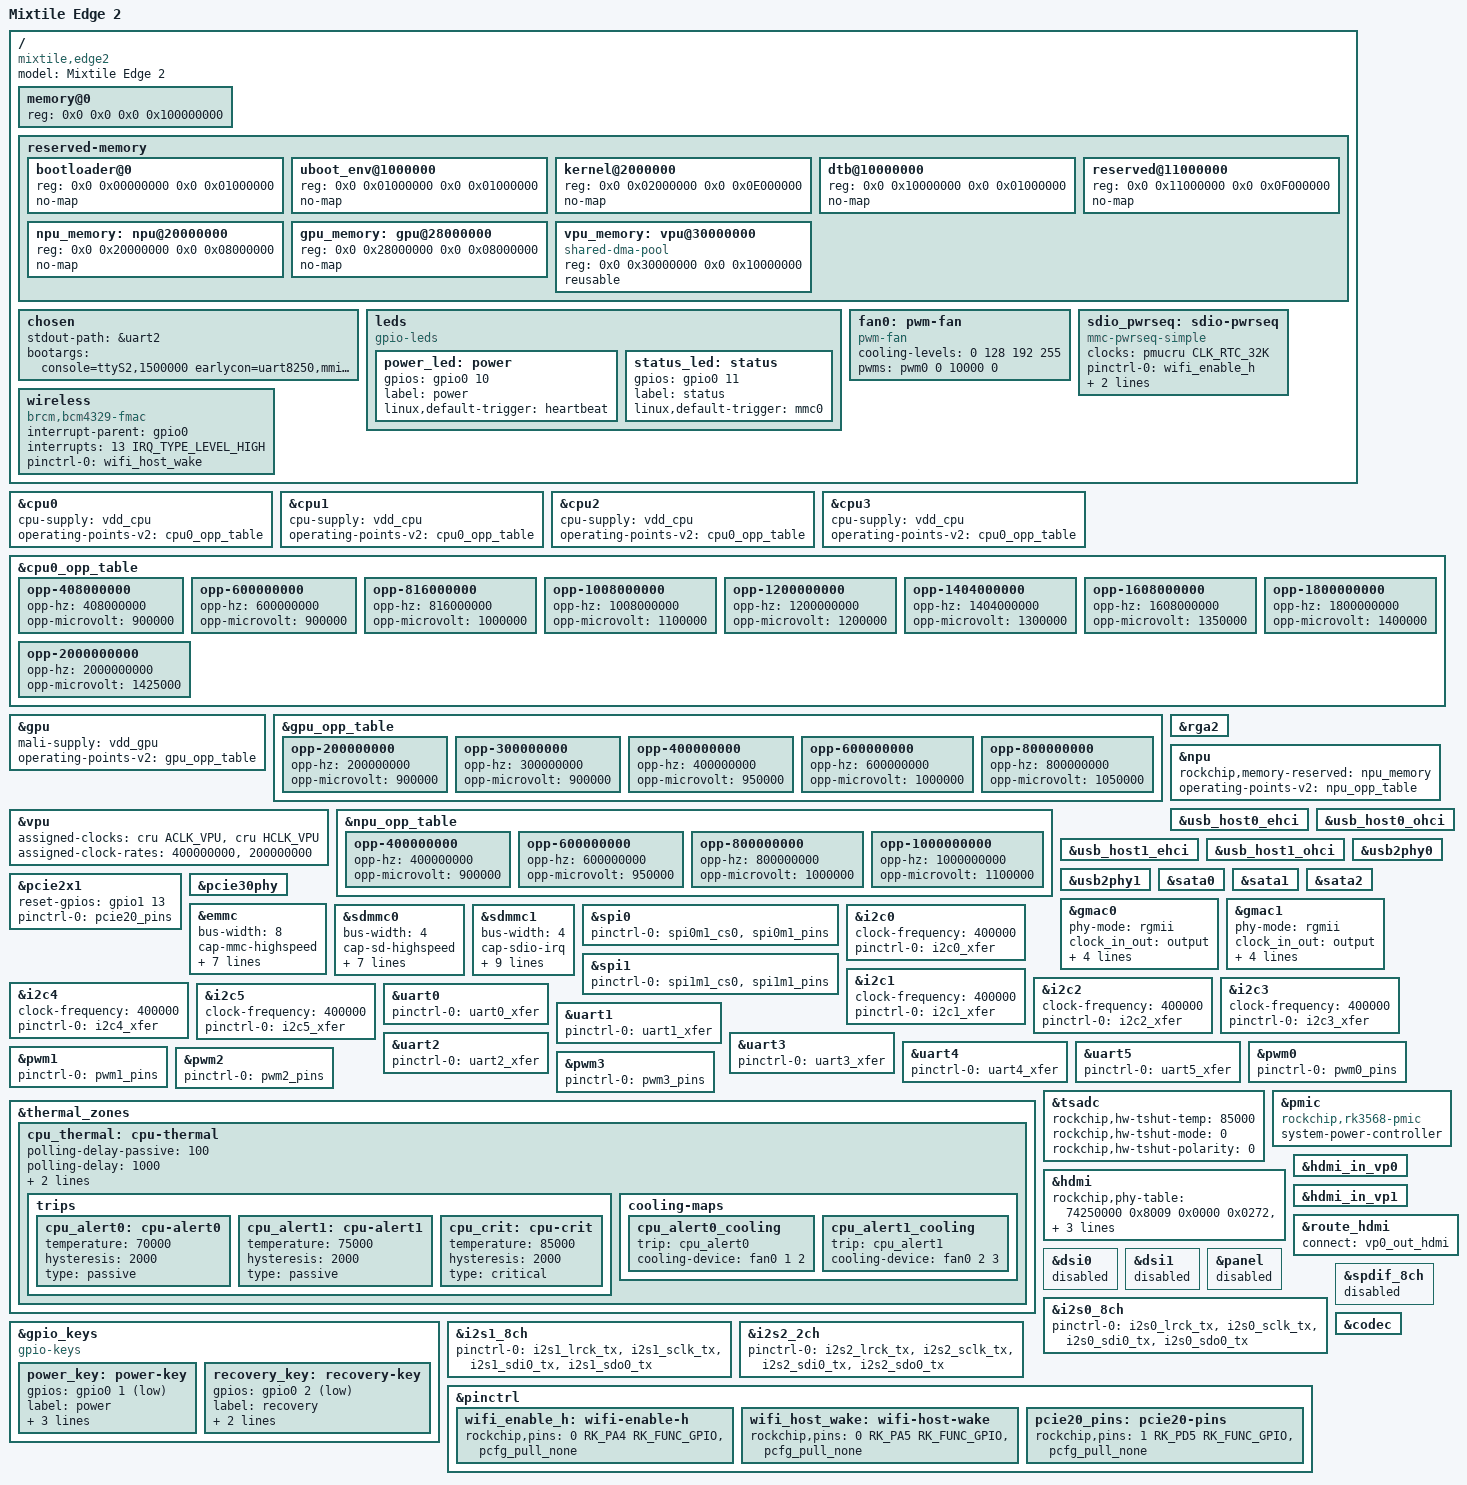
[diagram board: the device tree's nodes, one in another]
// SPDX-License-Identifier: (GPL-2.0+ OR MIT)
/*
 * Device Tree for Mixtile Edge 2
 * Based on Rockchip RK3568
 *
 * Copyright (C) 2024 Sebastian
 * All rights reserved.
 */

/dts-v1/;
#include "rk3568.dtsi"

/ {
	model = "Mixtile Edge 2";
	compatible = "mixtile,edge2", "rockchip,rk3568";

	/* Memory Configuration - 4GB LPDDR4 */
	memory@0 {
		device_type = "memory";
		reg = <0x0 0x0 0x0 0x100000000>;
	};

	/* Reserved Memory Regions */
	reserved-memory {
		#address-cells = <2>;
		#size-cells = <2>;
		ranges;

		/* Bootloader Region */
		bootloader@0 {
			reg = <0x0 0x00000000 0x0 0x01000000>;
			no-map;
			status = "okay";
		};

		/* U-Boot Environment */
		uboot_env@1000000 {
			reg = <0x0 0x01000000 0x0 0x01000000>;
			no-map;
			status = "okay";
		};

		/* Linux Kernel */
		kernel@2000000 {
			reg = <0x0 0x02000000 0x0 0x0E000000>;
			no-map;
			status = "okay";
		};

		/* Device Tree Blob */
		dtb@10000000 {
			reg = <0x0 0x10000000 0x0 0x01000000>;
			no-map;
			status = "okay";
		};

		/* Reserved System Region */
		reserved@11000000 {
			reg = <0x0 0x11000000 0x0 0x0F000000>;
			no-map;
			status = "okay";
		};

		/* NPU Memory Pool - 128MB */
		npu_memory: npu@20000000 {
			reg = <0x0 0x20000000 0x0 0x08000000>;
			no-map;
			status = "okay";
		};

		/* GPU Memory Pool - 128MB */
		gpu_memory: gpu@28000000 {
			reg = <0x0 0x28000000 0x0 0x08000000>;
			no-map;
			status = "okay";
		};

		/* VPU/Camera Buffers - 256MB CMA */
		vpu_memory: vpu@30000000 {
			compatible = "shared-dma-pool";
			reg = <0x0 0x30000000 0x0 0x10000000>;
			reusable;
			status = "okay";
		};
	};

	/* Board-Specific Properties */
	chosen {
		stdout-path = &uart2;
		bootargs = "console=ttyS2,1500000 earlycon=uart8250,mmio32,0xfe660000 root=/dev/mmcblk0p5 rw rootwait";
	};

	/* GPIO LED */
	leds {
		compatible = "gpio-leds";
		status = "okay";

		power_led: power {
			gpios = <&gpio0 10 GPIO_ACTIVE_HIGH>;
			label = "power";
			linux,default-trigger = "heartbeat";
		};

		status_led: status {
			gpios = <&gpio0 11 GPIO_ACTIVE_HIGH>;
			label = "status";
			linux,default-trigger = "mmc0";
		};
	};

	/* Fan Control */
	fan0: pwm-fan {
		compatible = "pwm-fan";
		cooling-levels = <0 128 192 255>;
		#cooling-cells = <2>;
		pwms = <&pwm0 0 10000 0>;
		status = "okay";
	};

	/* SD Card Detection */
	sdio_pwrseq: sdio-pwrseq {
		compatible = "mmc-pwrseq-simple";
		clocks = <&pmucru CLK_RTC_32K>;
		clock-names = "ext_clock";
		pinctrl-names = "default";
		pinctrl-0 = <&wifi_enable_h>;
		post-power-on-delay-ms = <200>;
		reset-gpios = <&gpio0 12 GPIO_ACTIVE_LOW>;
		status = "okay";
	};

	/* Wi-Fi/BT Module */
	wireless {
		compatible = "brcm,bcm4329-fmac";
		interrupt-parent = <&gpio0>;
		interrupts = <13 IRQ_TYPE_LEVEL_HIGH>;
		interrupt-names = "host-wake";
		pinctrl-names = "default";
		pinctrl-0 = <&wifi_host_wake>;
		status = "okay";
	};
};

/* SoC-Specific Configuration */

/* CPU Frequency Scaling */
&cpu0 {
	cpu-supply = <&vdd_cpu>;
	operating-points-v2 = <&cpu0_opp_table>;
};

&cpu1 {
	cpu-supply = <&vdd_cpu>;
	operating-points-v2 = <&cpu0_opp_table>;
};

&cpu2 {
	cpu-supply = <&vdd_cpu>;
	operating-points-v2 = <&cpu0_opp_table>;
};

&cpu3 {
	cpu-supply = <&vdd_cpu>;
	operating-points-v2 = <&cpu0_opp_table>;
};

/* CPU OPP Table */
&cpu0_opp_table {
	opp-408000000 {
		opp-hz = /bits/ 64 <408000000>;
		opp-microvolt = <900000>;
	};
	opp-600000000 {
		opp-hz = /bits/ 64 <600000000>;
		opp-microvolt = <900000>;
	};
	opp-816000000 {
		opp-hz = /bits/ 64 <816000000>;
		opp-microvolt = <1000000>;
	};
	opp-1008000000 {
		opp-hz = /bits/ 64 <1008000000>;
		opp-microvolt = <1100000>;
	};
	opp-1200000000 {
		opp-hz = /bits/ 64 <1200000000>;
		opp-microvolt = <1200000>;
	};
	opp-1404000000 {
		opp-hz = /bits/ 64 <1404000000>;
		opp-microvolt = <1300000>;
	};
	opp-1608000000 {
		opp-hz = /bits/ 64 <1608000000>;
		opp-microvolt = <1350000>;
	};
	opp-1800000000 {
		opp-hz = /bits/ 64 <1800000000>;
		opp-microvolt = <1400000>;
	};
	opp-2000000000 {
		opp-hz = /bits/ 64 <2000000000>;
		opp-microvolt = <1425000>;
	};
};

/* GPU Configuration */
&gpu {
	status = "okay";
	mali-supply = <&vdd_gpu>;
	operating-points-v2 = <&gpu_opp_table>;
};

&gpu_opp_table {
	opp-200000000 {
		opp-hz = /bits/ 64 <200000000>;
		opp-microvolt = <900000>;
	};
	opp-300000000 {
		opp-hz = /bits/ 64 <300000000>;
		opp-microvolt = <900000>;
	};
	opp-400000000 {
		opp-hz = /bits/ 64 <400000000>;
		opp-microvolt = <950000>;
	};
	opp-600000000 {
		opp-hz = /bits/ 64 <600000000>;
		opp-microvolt = <1000000>;
	};
	opp-800000000 {
		opp-hz = /bits/ 64 <800000000>;
		opp-microvolt = <1050000>;
	};
};

/* VPU Configuration */
&vpu {
	status = "okay";
	assigned-clocks = <&cru ACLK_VPU>, <&cru HCLK_VPU>;
	assigned-clock-rates = <400000000>, <200000000>;
};

/* RGA2 (Raster Graphics Accelerator) */
&rga2 {
	status = "okay";
};

/* NPU Configuration */
&npu {
	status = "okay";
	rockchip,memory-reserved = <&npu_memory>;
	operating-points-v2 = <&npu_opp_table>;
};

&npu_opp_table {
	opp-400000000 {
		opp-hz = /bits/ 64 <400000000>;
		opp-microvolt = <900000>;
	};
	opp-600000000 {
		opp-hz = /bits/ 64 <600000000>;
		opp-microvolt = <950000>;
	};
	opp-800000000 {
		opp-hz = /bits/ 64 <800000000>;
		opp-microvolt = <1000000>;
	};
	opp-1000000000 {
		opp-hz = /bits/ 64 <1000000000>;
		opp-microvolt = <1100000>;
	};
};

/* USB Configuration */
&usb_host0_ehci {
	status = "okay";
};

&usb_host0_ohci {
	status = "okay";
};

&usb_host1_ehci {
	status = "okay";
};

&usb_host1_ohci {
	status = "okay";
};

&usb2phy0 {
	status = "okay";
};

&usb2phy1 {
	status = "okay";
};

/* SATA Configuration */
&sata0 {
	status = "okay";
};

&sata1 {
	status = "okay";
};

&sata2 {
	status = "okay";
};

/* PCIe Configuration */
&pcie2x1 {
	status = "okay";
	reset-gpios = <&gpio1 13 GPIO_ACTIVE_HIGH>;
	pinctrl-names = "default";
	pinctrl-0 = <&pcie20_pins>;
};

&pcie30phy {
	status = "okay";
};

/* Ethernet */
&gmac0 {
	status = "okay";
	phy-mode = "rgmii";
	clock_in_out = "output";
	snps,reset-gpio = <&gpio2 18 GPIO_ACTIVE_LOW>;
	snps,reset-active-low;
	snps,reset-delays-us = <0 20000 100000>;
	pinctrl-names = "default";
	pinctrl-0 = <&gmac0_miim>;
};

&gmac1 {
	status = "okay";
	phy-mode = "rgmii";
	clock_in_out = "output";
	snps,reset-gpio = <&gpio2 19 GPIO_ACTIVE_LOW>;
	snps,reset-active-low;
	snps,reset-delays-us = <0 20000 100000>;
	pinctrl-names = "default";
	pinctrl-0 = <&gmac1_miim>;
};

/* eMMC */
&emmc {
	status = "okay";
	bus-width = <8>;
	cap-mmc-highspeed;
	mmc-hs200-1_8v;
	mmc-hs400-1_8v;
	supports-emmc;
	no-sdio;
	no-sd;
	non-removable;
	max-frequency = <200000000>;
};

/* SD Card */
&sdmmc0 {
	status = "okay";
	bus-width = <4>;
	cap-sd-highspeed;
	cd-gpios = <&gpio0 6 GPIO_ACTIVE_LOW>;
	disable-wp;
	pinctrl-names = "default";
	pinctrl-0 = <&sdmmc0_bus4 &sdmmc0_clk &sdmmc0_cmd &sdmmc0_detect>;
	max-frequency = <150000000>;
	vmmc-supply = <&vcc3v3_sd>;
	vqmmc-supply = <&vcc_1v8>;
};

/* SDIO (Wi-Fi) */
&sdmmc1 {
	status = "okay";
	bus-width = <4>;
	cap-sdio-irq;
	cap-sd-highspeed;
	keep-power-in-suspend;
	mmc-pwrseq = <&sdio_pwrseq>;
	non-removable;
	pinctrl-names = "default";
	pinctrl-0 = <&sdmmc1_bus4 &sdmmc1_clk &sdmmc1_cmd>;
	sd-uhs-sdr104;
	supports-sdio;
	vmmc-supply = <&vcc3v3_sd>;
	vqmmc-supply = <&vcc_1v8>;
};

/* SPI */
&spi0 {
	status = "okay";
	pinctrl-names = "default";
	pinctrl-0 = <&spi0m1_cs0 &spi0m1_pins>;
};

&spi1 {
	status = "okay";
	pinctrl-names = "default";
	pinctrl-0 = <&spi1m1_cs0 &spi1m1_pins>;
};

/* I2C */
&i2c0 {
	status = "okay";
	clock-frequency = <400000>;
	pinctrl-names = "default";
	pinctrl-0 = <&i2c0_xfer>;
};

&i2c1 {
	status = "okay";
	clock-frequency = <400000>;
	pinctrl-names = "default";
	pinctrl-0 = <&i2c1_xfer>;
};

&i2c2 {
	status = "okay";
	clock-frequency = <400000>;
	pinctrl-names = "default";
	pinctrl-0 = <&i2c2_xfer>;
};

&i2c3 {
	status = "okay";
	clock-frequency = <400000>;
	pinctrl-names = "default";
	pinctrl-0 = <&i2c3_xfer>;
};

&i2c4 {
	status = "okay";
	clock-frequency = <400000>;
	pinctrl-names = "default";
	pinctrl-0 = <&i2c4_xfer>;
};

&i2c5 {
	status = "okay";
	clock-frequency = <400000>;
	pinctrl-names = "default";
	pinctrl-0 = <&i2c5_xfer>;
};

/* UART */
&uart0 {
	status = "okay";
	pinctrl-names = "default";
	pinctrl-0 = <&uart0_xfer>;
};

&uart1 {
	status = "okay";
	pinctrl-names = "default";
	pinctrl-0 = <&uart1_xfer>;
};

&uart2 {
	status = "okay";
	pinctrl-names = "default";
	pinctrl-0 = <&uart2_xfer>;
};

&uart3 {
	status = "okay";
	pinctrl-names = "default";
	pinctrl-0 = <&uart3_xfer>;
};

&uart4 {
	status = "okay";
	pinctrl-names = "default";
	pinctrl-0 = <&uart4_xfer>;
};

&uart5 {
	status = "okay";
	pinctrl-names = "default";
	pinctrl-0 = <&uart5_xfer>;
};

/* PWM */
&pwm0 {
	status = "okay";
	pinctrl-names = "default";
	pinctrl-0 = <&pwm0_pins>;
};

&pwm1 {
	status = "okay";
	pinctrl-names = "default";
	pinctrl-0 = <&pwm1_pins>;
};

&pwm2 {
	status = "okay";
	pinctrl-names = "default";
	pinctrl-0 = <&pwm2_pins>;
};

&pwm3 {
	status = "okay";
	pinctrl-names = "default";
	pinctrl-0 = <&pwm3_pins>;
};

/* Thermal */
&thermal_zones {
	cpu_thermal: cpu-thermal {
		polling-delay-passive = <100>;
		polling-delay = <1000>;
		sustainable-power = <4500>;
		thermal-sensors = <&tsadc 0>;

		trips {
			cpu_alert0: cpu-alert0 {
				temperature = <70000>;
				hysteresis = <2000>;
				type = "passive";
			};
			cpu_alert1: cpu-alert1 {
				temperature = <75000>;
				hysteresis = <2000>;
				type = "passive";
			};
			cpu_crit: cpu-crit {
				temperature = <85000>;
				hysteresis = <2000>;
				type = "critical";
			};
		};

		cooling-maps {
			cpu_alert0_cooling {
				trip = <&cpu_alert0>;
				cooling-device = <&fan0 1 2>;
			};
			cpu_alert1_cooling {
				trip = <&cpu_alert1>;
				cooling-device = <&fan0 2 3>;
			};
		};
	};
};

/* TSADC (Thermal Sensor) */
&tsadc {
	status = "okay";
	rockchip,hw-tshut-temp = <85000>;
	rockchip,hw-tshut-mode = <0>;
	rockchip,hw-tshut-polarity = <0>;
	/* pinctrl-names = "default"; */
	/* pinctrl-0 = <&tsadc_pin>; */
};

/* PMIC */
&pmic {
	status = "okay";
	compatible = "rockchip,rk3568-pmic";
	system-power-controller;
};

/* GPIO Keys */
&gpio_keys {
	status = "okay";
	compatible = "gpio-keys";

	power_key: power-key {
		gpios = <&gpio0 1 GPIO_ACTIVE_LOW>;
		label = "power";
		linux,code = <KEY_POWER>;
		debounce-interval = <100>;
		wakeup-source;
	};

	recovery_key: recovery-key {
		gpios = <&gpio0 2 GPIO_ACTIVE_LOW>;
		label = "recovery";
		linux,code = <KEY_RESTART>;
		debounce-interval = <100>;
	};
};

/* Display */
&hdmi {
	status = "okay";
	rockchip,phy-table =
		<74250000 0x8009 0x0000 0x0272>,
		<148500000 0x8029 0x0000 0x0272>,
		<296703000 0x8039 0x0000 0x0272>,
		<594000000 0x8039 0x0000 0x0272>;
};

&hdmi_in_vp0 {
	status = "okay";
};

&hdmi_in_vp1 {
	status = "okay";
};

&route_hdmi {
	status = "okay";
	connect = <&vp0_out_hdmi>;
};

/* MIPI DSI */
&dsi0 {
	status = "disabled";  /* Enable if using MIPI display */
};

&dsi1 {
	status = "disabled";
};

/* Panel */
&panel {
	status = "disabled";
};

/* Audio */
&i2s0_8ch {
	status = "okay";
	pinctrl-names = "default";
	pinctrl-0 = <&i2s0_lrck_tx &i2s0_sclk_tx &i2s0_sdi0_tx &i2s0_sdo0_tx>;
};

&i2s1_8ch {
	status = "okay";
	pinctrl-names = "default";
	pinctrl-0 = <&i2s1_lrck_tx &i2s1_sclk_tx &i2s1_sdi0_tx &i2s1_sdo0_tx>;
};

&i2s2_2ch {
	status = "okay";
	pinctrl-names = "default";
	pinctrl-0 = <&i2s2_lrck_tx &i2s2_sclk_tx &i2s2_sdi0_tx &i2s2_sdo0_tx>;
};

/* SPDIF */
&spdif_8ch {
	status = "disabled";
};

/* Codec */
&codec {
	status = "okay";
};

/* Pinctrl Overrides */
&pinctrl {
	/* SDIO Wi-Fi */
	wifi_enable_h: wifi-enable-h {
		rockchip,pins = <0 RK_PA4 RK_FUNC_GPIO &pcfg_pull_none>;
	};

	wifi_host_wake: wifi-host-wake {
		rockchip,pins = <0 RK_PA5 RK_FUNC_GPIO &pcfg_pull_none>;
	};

	/* PCIe */
	pcie20_pins: pcie20-pins {
		rockchip,pins = <1 RK_PD5 RK_FUNC_GPIO &pcfg_pull_none>;
	};
};
